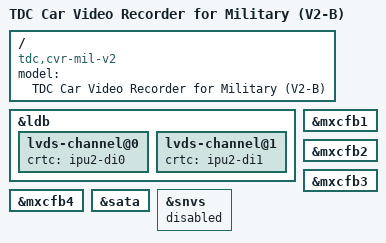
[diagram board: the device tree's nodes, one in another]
/*
 * Technology Development Co.,Ltd
 * http://www.nedi.com.cn
 * Varphone Wong <varphone@qq.com>
 */

/dts-v1/;
#include "imx6q.dtsi"
#include "myimx6ek200-cm.dtsi"

/ {
	model = "TDC Car Video Recorder for Military (V2-B)";
	compatible = "tdc,cvr-mil-v2", "myzr,myimx6", "myzr,myimx6q", "myzr,myimx6cb200", "myzr,myimx6ek200", "fsl,imx6q", "fsl,imx6q-ldb";
};

&ldb {
	lvds-channel@0 {
		crtc = "ipu2-di0";
	};
	lvds-channel@1 {
		crtc = "ipu2-di1";
	};
};

&mxcfb1 {
	status = "okay";
};

&mxcfb2 {
	status = "okay";
};

&mxcfb3 {
	status = "okay";
};

&mxcfb4 {
	status = "okay";
};

&sata {
	status = "okay";
};

&snvs {
	status = "disabled";
};
